# LCM32F039 register map
File version: 1.0
CPU: CM0 r1p0, little endian, MPU, no FPU, 3 interrupt priority bits
Registers are 32-bit, read-write, reset 0x0 unless marked. A register's access mark holds for its fields unless they carry their own. Offsets are from the block's base; [hi:lo] are bit positions; {n}, {i} and the like mark numbered series; 'fields as' and 'values as' point back to an identical list.

## FLASH — eflash controller
Base 0x4001D000
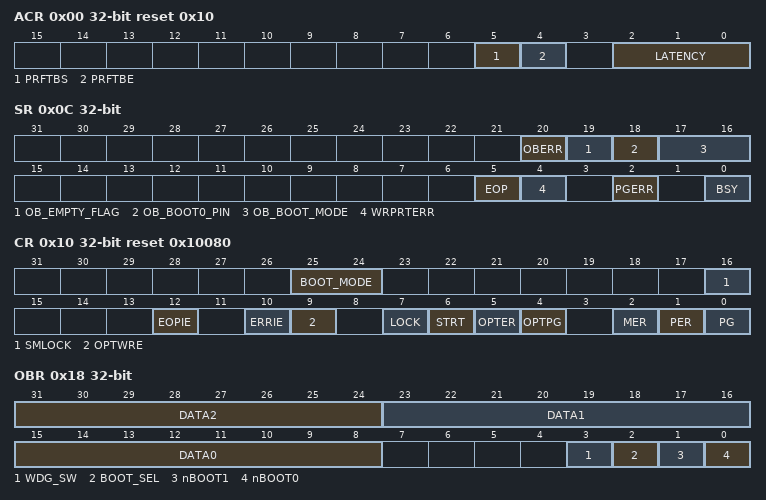
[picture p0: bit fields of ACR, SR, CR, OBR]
0x00 ACR reset 0x10 — Flash access control register
  [5] PRFTBS — Prefetch buffer status
  [4] PRFTBE — Prefetch buffer enable
  [2:0] LATENCY
0x04 KEYR wo — Flash key register
  [31:0] FKEY — Flash key
0x08 OPTKEYR wo — Flash option key register
  [31:0] OPTKEY — Option byte key
0x0C SR — Flash status register
  [20] OBERR ro — Option byte error
  [19] OB_EMPTY_FLAG ro — Main memory empty flag
  [18] OB_BOOT0_PIN ro — Boot0 pin value
  [17:16] OB_BOOT_MODE ro — Device boot mode configuration in option byte
  [5] EOP — End of operation
  [4] WRPRTERR — Write protection error
  [2] PGERR — Programming error
  [0] BSY ro — Busy flag
0x10 CR reset 0x10080 — Flash control register
  [25:24] BOOT_MODE — Device boot mode selection
  [16] SMLOCK — System memory write lock
  [12] EOPIE — End of operation interrupt enable
  [10] ERRIE — Error interrupt enable
  [9] OPTWRE — Option byte write enable
  [7] LOCK — in order to LOCK flash
  [6] STRT — Start
  [5] OPTER — Option byte erase
  [4] OPTPG — Option byte programming
  [2] MER — Mass erase
  [1] PER — Page erase
  [0] PG — Flash programming chosen
0x14 AR — Flash address register
  [31:0] FAR — Flash Address
0x18 OBR ro — Flash Option byte register
  [31:24] DATA2, [23:16] DATA1, [15:8] DATA0, [3] WDG_SW, [2] BOOT_SEL, [1] nBOOT1, [0] nBOOT0
0x1C CAL1 ro — The reset value of this register depends on the value programmed in the option byte.
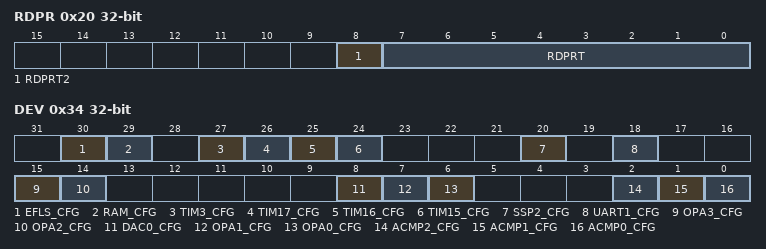
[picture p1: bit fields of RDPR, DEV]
0x20 RDPR ro — Flash read protection register.
  [8] RDPRT2 — The whole flash read protection level 2 status
  [7:0] RDPRT — The 8 flash regions read protection level status
0x24 WRPR ro — The reset value of this register depends on the value programmed in the option byte
  [31:0] WRP — Write protect
{0x20+4i} CAL{i} ro (i=2..4) — Flash calibration register {i}
0x34 DEV ro — Device
  [30] EFLS_CFG
  [29] RAM_CFG
  [27] TIM3_CFG
  [26] TIM17_CFG
  [25] TIM16_CFG
  [24] TIM15_CFG
  [20] SSP2_CFG
  [18] UART1_CFG
  [15] OPA3_CFG
  [14] OPA2_CFG
  [8] DAC0_CFG — DACO_CFG
  [7] OPA1_CFG
  [6] OPA0_CFG
  [2] ACMP2_CFG
  [1] ACMP1_CFG
  [0] ACMP0_CFG
0x3C SMKEYR wo — System Storage Key Register
  [31:0] SMKEY

## GPIOF — General-purpose I/Os
Base 0x48000A00
Same registers: GPIOA 0x48000000, GPIOB 0x48000200, GPIOC 0x48000400
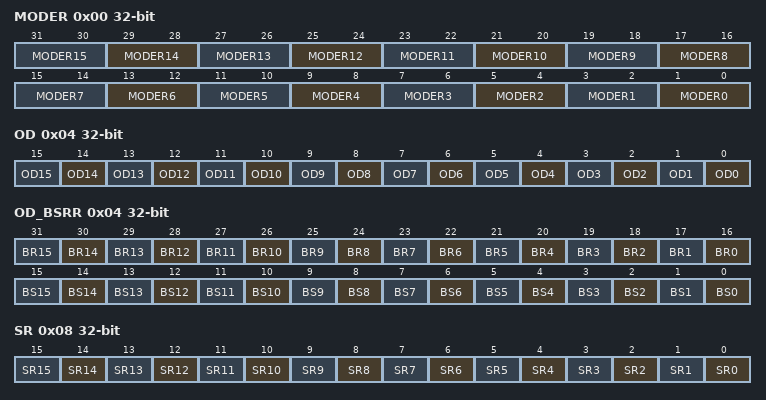
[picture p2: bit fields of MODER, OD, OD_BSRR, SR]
0x00 MODER — GPIO port mode register
  [2n+1:2n] MODER{n} (n=0..15) — Port x configuration bits (y = 0..15)
0x04 OD ro — GPIO port open drain bit set/reset register
  [n] OD{n} (n=0..15) — Port x open drain configuration bits (y = 0..15)
0x04 OD_BSRR (alternate view of OD) — GPIO port open drain bit set/reset register
  [n+16] BR{n} (n=0..15) — Port x open drain configuration reset bits (y = 0..15)
  [n] BS{n} (n=0..15) — Port x open drain configuration set bits (y = 0..15)
0x08 SR ro — GPIO port slew rate bit set/reset register
  [n] SR{n} (n=0..15) — Port x open drain configuration reset bits (y = 0..15)
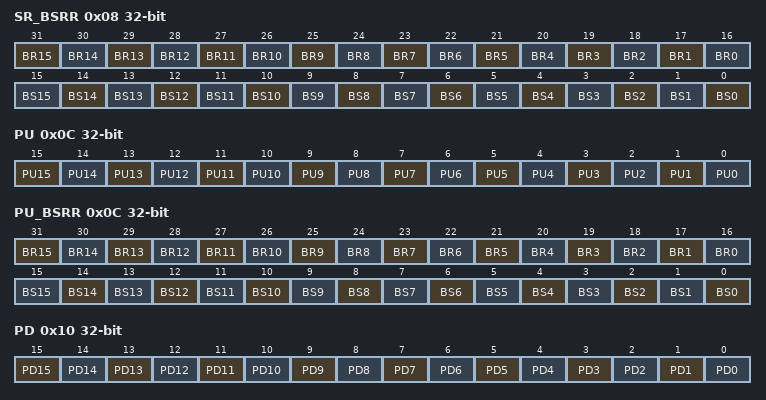
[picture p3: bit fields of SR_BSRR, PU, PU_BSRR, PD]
0x08 SR_BSRR (alternate view of SR) — GPIO port slew rate bit set/reset register
  [n+16] BR{n} (n=1..15) — Port x open drain configuration reset bits (y = 0..15)
  [16] BR0 — Port x slew rate configuration reset bits (y = 0..15)
  [n] BS{n} (n=0..15) — Port x slew rate configuration bits (y = 0..15)
0x0C PU ro — GPIO port pull up bit set/reset register
  [n] PU{n} (n=1..15) — Port x slew rate configuration bits (y = 0..15)
  [0] PU0 — Port x pull up configuration bits (y = 0..15)
0x0C PU_BSRR (alternate view of PU) — GPIO port pull up bit set/reset register
  [n+16] BR{n} (n=1..15) — Port x slew rate configuration bits (y = 0..15)
  [16] BR0 — Port x pull up configuration reset bits (y = 0..15)
  [n] BS{n} (n=0..15) — Port x pull up configuration set bits (y = 0..15)
0x10 PD ro — GPIO port pull down bit set/reset register
  [n] PD{n} (n=1..15) — Port x slew rate configuration bits (y = 0..15)
  [0] PD0 — Port x pull down configuration bits (y = 0..15)
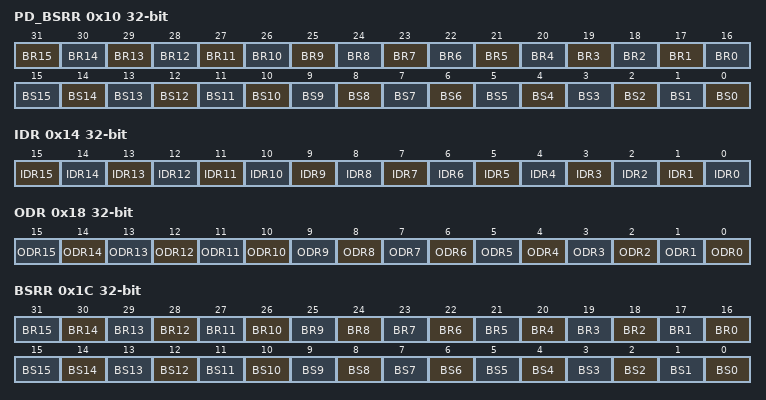
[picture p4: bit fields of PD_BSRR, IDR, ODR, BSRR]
0x10 PD_BSRR (alternate view of PD) — GPIO port pull down bit set/reset register
  fields as PU_BSRR
0x14 IDR — GPIO port input data register
  [n] IDR{n} (n=1..15) — Port x slew rate configuration bits (y = 0..15)
  [0] IDR0 — Port x pull up configuration reset bits (y = 0..15)
0x18 ODR — GPIO port output data register
  [n] ODR{n} (n=0..15)
0x1C BSRR — GPIO bit set reset register
  [n+16] BR{n} (n=0..15), [n] BS{n} (n=0..15)
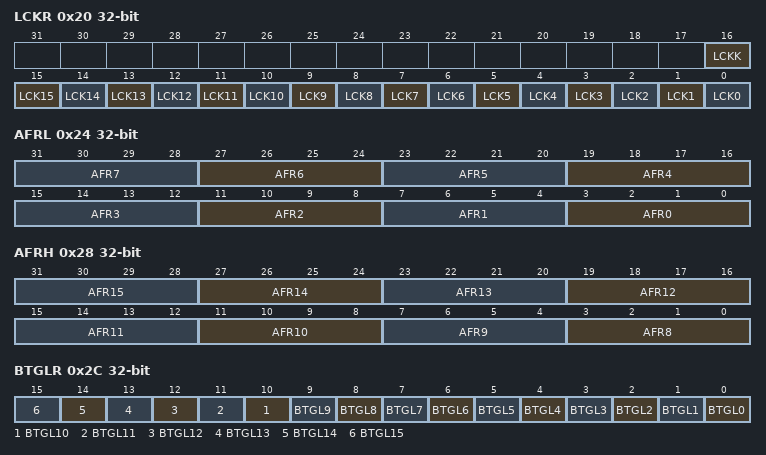
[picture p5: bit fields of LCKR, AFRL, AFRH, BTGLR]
0x20 LCKR — GPIO lock register
  [16] LCKK, [n] LCK{n} (n=0..15)
0x24 AFRL — GPIO AF register
  [4n+3:4n] AFR{n} (n=0..7)
0x28 AFRH — GPIO AF register
  [4n-29:4n-32] AFR{n} (n=8..15)
0x2C BTGLR — GPIO output bit troggle
  [n] BTGL{n} (n=0..15)
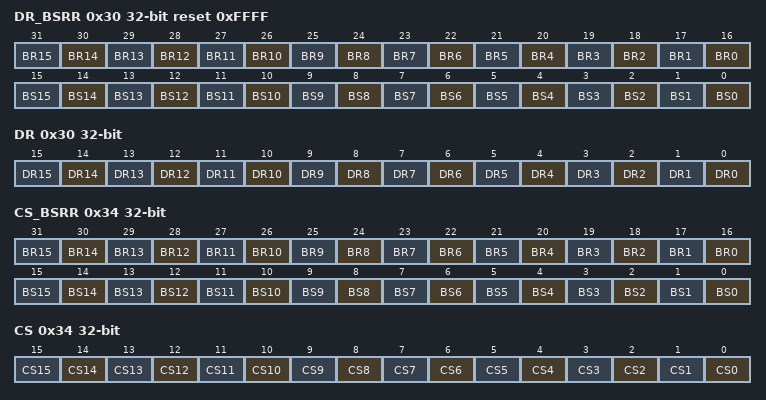
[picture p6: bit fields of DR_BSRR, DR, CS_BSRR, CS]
0x30 DR_BSRR reset 0xFFFF — GPIO port driving strength bit set/reset register
  [n+16] BR{n} (n=0..15), [n] BS{n} (n=0..15)
0x30 DR ro (alternate view of DR_BSRR) — return GPIO port driving strength when read
  [n] DR{n} (n=0..15)
0x34 CS_BSRR — GPIO port cmos/schmitt bit set/reset register
  [n+16] BR{n} (n=0..15), [n] BS{n} (n=0..15)
0x34 CS ro (alternate view of CS_BSRR) — return GPIO port cmos/schmitt when read
  [n] CS{n} (n=0..15)
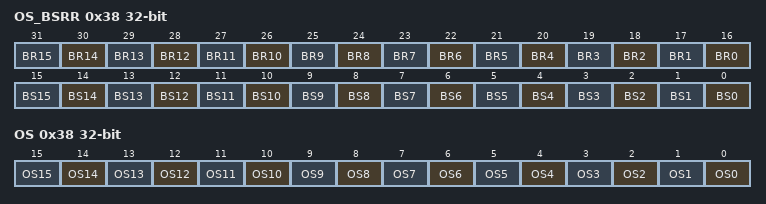
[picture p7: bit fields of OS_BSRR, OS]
0x38 OS_BSRR — GPIO port open source bit set/reset register
  [n+16] BR{n} (n=0..15), [n] BS{n} (n=0..15)
0x38 OS ro (alternate view of OS_BSRR) — return GPIO port open source when read
  [n] OS{n} (n=0..15)
